# R7FA4L1BD register map
Vendor: Renesas Electronics Corporation; Series: RA4; File version: 0.90.02
CPU: CM33 r0p4, little endian, MPU, FPU, VTOR, 4 interrupt priority bits, 96 interrupts
Registers are 32-bit, read-write, reset 0x0 unless marked. A register's access mark holds for its fields unless they carry their own. Offsets are from the block's base; [hi:lo] are bit positions.

## FACI — Flash/CPU Interface
Base 0x407FE000
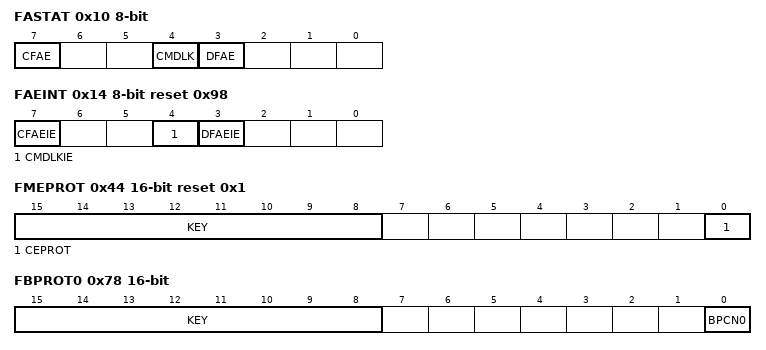
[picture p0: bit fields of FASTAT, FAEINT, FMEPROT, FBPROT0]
0x10 FASTAT 8-bit — Flash Access Status Register
  [7] CFAE — Code Flash Memory Access Violation Flag
  [4] CMDLK ro — Command Lock Flag
  [3] DFAE — Data Flash Memory Access Violation Flag
0x14 FAEINT 8-bit reset 0x98 — Flash Access Error Interrupt Enable Register
  [7] CFAEIE — Code Flash Memory Access Violation Interrupt Enable
  [4] CMDLKIE — Command Lock Interrupt Enable
  [3] DFAEIE — Data Flash Memory Access Violation Interrupt Enable
0x18 FRDYIE 8-bit — Flash Ready Interrupt Enable Register
  [0] FRDYIE — Flash Ready Interrupt Enable
0x30 FSADDR — FACI Command Start Address Register
  [31:0] FSADDR — Start Address for FACI Command Processing
0x34 FEADDR — FACI Command End Address Register
  [31:0] FEADDR — End Address for FACI Command Processing
0x44 FMEPROT 16-bit reset 0x1 — Flash P/E Mode Entry Protection Register
  [15:8] KEY wo — Key Code
  [0] CEPROT — Code Flash P/E Mode Entry Protection
0x78 FBPROT0 16-bit — Flash Block Protection Register
  [15:8] KEY wo — Key Code
  [0] BPCN0 — Block Protection for Non,secure Cancel
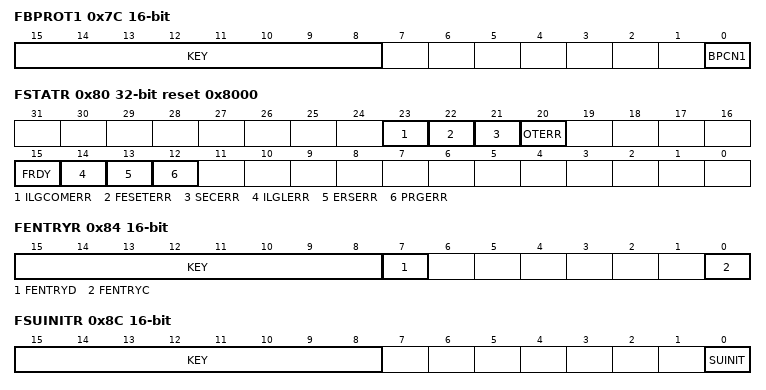
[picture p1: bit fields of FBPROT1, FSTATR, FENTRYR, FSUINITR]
0x7C FBPROT1 16-bit — Flash Block Protection for Secure Register
  [15:8] KEY wo — Key Code
  [0] BPCN1 — Block Protection for Secure Cancel
0x80 FSTATR reset 0x8000 — Flash Status Register
  [23] ILGCOMERR ro — Illegal Command Error
  [22] FESETERR ro — FENTRY Setting Error
  [21] SECERR ro — Security Error
  [20] OTERR ro — Other Error
  [15] FRDY ro — Flash Ready Flag
  [14] ILGLERR ro — Illegal Command Error Flag
  [13] ERSERR ro — Erasure Error Flag
  [12] PRGERR ro — Programming Error Flag
0x84 FENTRYR 16-bit — Flash P/E Mode Entry Register
  [15:8] KEY wo — Key Code
  [7] FENTRYD — Data Flash P/E Mode Entry
  [0] FENTRYC — Code Flash P/E Mode Entry
0x8C FSUINITR 16-bit — Flash Sequencer Setup Initialization Register
  [15:8] KEY wo — Key Code
  [0] SUINIT — Set,Up Initialization
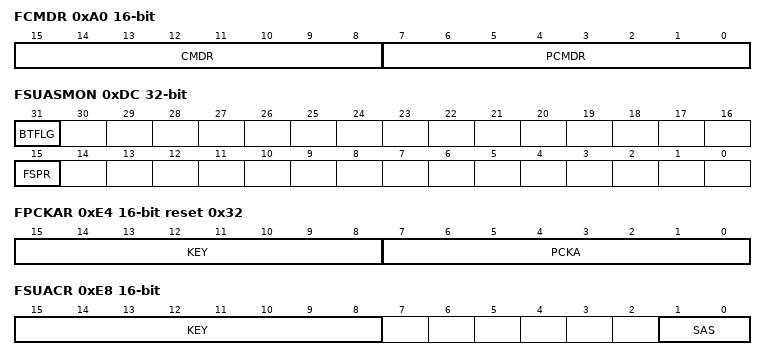
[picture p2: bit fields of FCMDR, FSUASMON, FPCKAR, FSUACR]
0xA0 FCMDR 16-bit ro — FACI Command Register
  [15:8] CMDR — Command Flag
  [7:0] PCMDR — Pre,command Flag
0xD0 FBCCNT 8-bit — Blank Check Control Register
  [0] BCDIR — Blank Check Direction
0xD4 FBCSTAT 8-bit — Blank Check Status Register
  [0] BCST ro — Blank Check Status Flag
0xD8 FBCADDR — Flash Blank Check Address Register
  [23:0] BCADR ro — Blank Check Address
0xDC FSUASMON ro (reset mask 0x7FFF7FFF) — Flash Startup Area Select Monitor Register
  [31] BTFLG — Flag of Startup Area Select for Boot Swap
  [15] FSPR — Protection Programming Flag to set Boot Flag, Startup Area Control, and Chip Erase
0xE4 FPCKAR 16-bit reset 0x32 — Flash Sequencer Processing Clock Notification Register
  [15:8] KEY wo — Key Code
  [7:0] PCKA — Flash Sequencer Operating Clock Notification
0xE8 FSUACR 16-bit — Flash Startup Area Control Register
  [15:8] KEY wo — Key Code
  [1:0] SAS — Startup Area Select

## QSPI — Quad Serial Peripheral Interface
Base 0x64000000
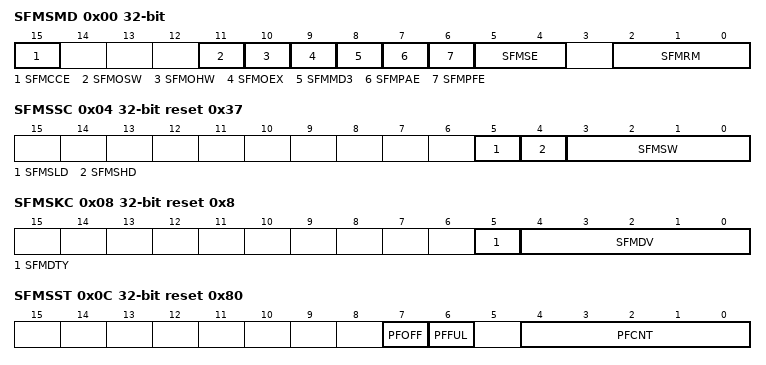
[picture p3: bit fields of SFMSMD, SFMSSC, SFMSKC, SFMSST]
0x00 SFMSMD — Transfer Mode Control Register
  [15] SFMCCE — Read instruction code select
  [11] SFMOSW — Setup time adjustment for serial transmission
  [10] SFMOHW — Hold time adjustment for serial transmission
  [9] SFMOEX — Extension select for the I/O buffer output enable signal for the serial interface
  [8] SFMMD3 — SPI mode select.
  [7] SFMPAE — Function select for stopping prefetch at locations other than on byte boundaries
  [6] SFMPFE — Prefetch function select
  [5:4] SFMSE — QSSL extension function select after SPI bus access
  [2:0] SFMRM — Serial interface read mode select
0x04 SFMSSC reset 0x37 — Chip Selection Control Register
  [5] SFMSLD — QSSL Signal Setup Time
  [4] SFMSHD — QSSL Signal Hold Time
  [3:0] SFMSW — Minimum High,level Width Select for QSSL Signal
0x08 SFMSKC reset 0x8 — Clock Control Register
  [5] SFMDTY — Duty ratio correction function select for the QSPCLK signal when devided by an odd number
  [4:0] SFMDV — Serial interface reference (QSPCLK) cycle select. (Pay attention to irregularities.)
0x0C SFMSST ro reset 0x80 — Status Register
  [7] PFOFF — Prefetch function operating state
  [6] PFFUL — Prefetch buffer state
  [4:0] PFCNT — Number of bytes of prefetched data
0x10 SFMCOM (reset mask 0xFFFFFF00) — Communication Port Register
  [7:0] SFMD — Port for direct communication with the SPI bus
0x14 SFMCMD — Communication Mode Control Register
  [0] DCOM — Mode select for communication with the SPI bus
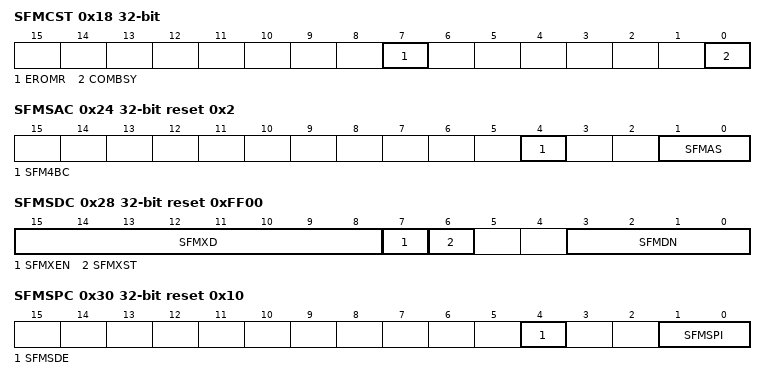
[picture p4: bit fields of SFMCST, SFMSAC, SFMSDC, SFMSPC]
0x18 SFMCST — Communication Status Register
  [7] EROMR — ROM access detection status in direct communication mode
  [0] COMBSY ro — SPI bus cycle completion state in direct communication
0x20 SFMSIC — Instruction Code Register
  [7:0] SFMCIC — Serial flash instruction code to substitute
0x24 SFMSAC reset 0x2 — Address Mode Control Register
  [4] SFM4BC — Selection of instruction code automatically generated when the serial interface address width is 4 bytes
  [1:0] SFMAS — Number of address bytes select for the serial interface
0x28 SFMSDC reset 0xFF00 — Dummy Cycle Control Register
  [15:8] SFMXD — Mode data for serial flash (Controls XIP mode.)
  [7] SFMXEN — XIP mode permission
  [6] SFMXST ro — XIP mode status
  [3:0] SFMDN — Number of dummy cycles select for Fast Read instructions
0x30 SFMSPC reset 0x10 — SPI Protocol Control Register
  [4] SFMSDE — QSPCLK extended selection bit when switching I/O of QIOn pin
  [1:0] SFMSPI — SPI protocol select
0x34 SFMPMD — Port Control Register
  [2] SFMWPL — WP pin level specification
0x804 SFMCNT1 — External QSPI Address Register
  [31:26] QSPI_EXT — Bank switching address

## CPU_OCD — OCD Function
Base 0x80000000
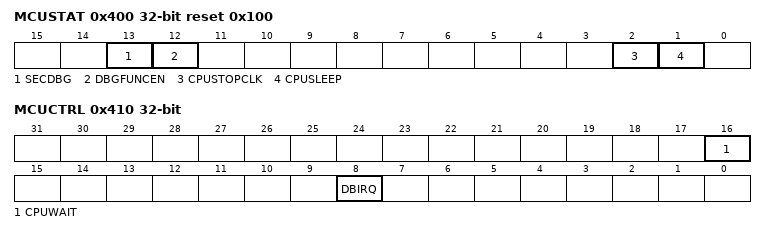
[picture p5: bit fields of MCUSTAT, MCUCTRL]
0x400 MCUSTAT ro reset 0x100 (reset mask 0xFFFFCFF9) — MCU Status Register
  [13] SECDBG — Secure Debug status
  [12] DBGFUNCEN — Debugger status
  [2] CPUSTOPCLK — CPU clock status
  [1] CPUSLEEP — Sleep mode status
0x410 MCUCTRL — MCU Control Register
  [16] CPUWAIT — CPU Wait Setting
  [8] DBIRQ — Debug Interrupt Request
